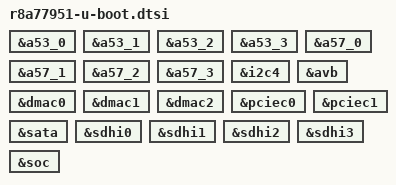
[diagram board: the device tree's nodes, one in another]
// SPDX-License-Identifier: GPL-2.0
/*
 * Device Tree Source extras for U-Boot on R-Car R8A7795 SoC
 *
 * Copyright (C) 2018 Marek Vasut <marek.vasut@gmail.com>
 */

/delete-node/ &ak4613;
/delete-node/ &audma0;
/delete-node/ &audma1;
/delete-node/ &can0;
/delete-node/ &can1;
/delete-node/ &canfd;
/delete-node/ &cluster0_opp;
/delete-node/ &cluster1_opp;
/delete-node/ &csi20;
/delete-node/ &csi40;
/delete-node/ &csi41;
/delete-node/ &drif00;
/delete-node/ &drif01;
/delete-node/ &drif10;
/delete-node/ &drif11;
/delete-node/ &drif20;
/delete-node/ &drif21;
/delete-node/ &drif30;
/delete-node/ &drif31;
/delete-node/ &du;
/delete-node/ &fcpf0;
/delete-node/ &fcpf1;
/delete-node/ &fcpvb0;
/delete-node/ &fcpvb1;
/delete-node/ &fcpvd0;
/delete-node/ &fcpvd1;
/delete-node/ &fcpvd2;
/delete-node/ &fcpvi0;
/delete-node/ &fcpvi1;
/delete-node/ &hdmi0;
/delete-node/ &hdmi1;
/delete-node/ &ipmmu_ds0;
/delete-node/ &ipmmu_ds1;
/delete-node/ &ipmmu_hc;
/delete-node/ &ipmmu_ir;
/delete-node/ &ipmmu_mm;
/delete-node/ &ipmmu_mp0;
/delete-node/ &ipmmu_pv0;
/delete-node/ &ipmmu_pv1;
/delete-node/ &ipmmu_pv2;
/delete-node/ &ipmmu_pv3;
/delete-node/ &ipmmu_rt;
/delete-node/ &ipmmu_vc0;
/delete-node/ &ipmmu_vc1;
/delete-node/ &ipmmu_vi0;
/delete-node/ &ipmmu_vi1;
/delete-node/ &ipmmu_vp0;
/delete-node/ &ipmmu_vp1;
/delete-node/ &lvds0;
/delete-node/ &rcar_sound;
/delete-node/ &sound_card;
/delete-node/ &vin0;
/delete-node/ &vin1;
/delete-node/ &vin2;
/delete-node/ &vin3;
/delete-node/ &vin4;
/delete-node/ &vin5;
/delete-node/ &vin6;
/delete-node/ &vin7;
/delete-node/ &vspbc;
/delete-node/ &vspbd;
/delete-node/ &vspd0;
/delete-node/ &vspd1;
/delete-node/ &vspd2;
/delete-node/ &vspi0;
/delete-node/ &vspi1;

/ {
	/delete-node/ cvbs-in;
	/delete-node/ hdmi-in;
	/delete-node/ hdmi0-out;
	/delete-node/ hdmi1-out;
	/delete-node/ vga-encoder;
	/delete-node/ vga;
};

&a53_0 {
	/delete-property/ operating-points-v2;
};

&a53_1 {
	/delete-property/ operating-points-v2;
};

&a53_2 {
	/delete-property/ operating-points-v2;
};

&a53_3 {
	/delete-property/ operating-points-v2;
};

&a57_0 {
	/delete-property/ operating-points-v2;
};

&a57_1 {
	/delete-property/ operating-points-v2;
};

&a57_2 {
	/delete-property/ operating-points-v2;
};

&a57_3 {
	/delete-property/ operating-points-v2;
};

&i2c4 {
	/delete-node/ video-receiver@70;
};

&avb {
	/delete-property/ iommus;
};

&dmac0 {
	/delete-property/ iommus;
};

&dmac1 {
	/delete-property/ iommus;
};

&dmac2 {
	/delete-property/ iommus;
};

&pciec0 {
	/delete-property/ iommu-map;
};

&pciec1 {
	/delete-property/ iommu-map;
};

&sata {
	/delete-property/ iommus;
};

&sdhi0 {
	/delete-property/ iommus;
};

&sdhi1 {
	/delete-property/ iommus;
};

&sdhi2 {
	/delete-property/ iommus;
};

&sdhi3 {
	/delete-property/ iommus;
};

&soc {
	/delete-node/ fdp1@fe940000;
	/delete-node/ fdp1@fe944000;
	/delete-node/ fdp1@fe948000;
	/delete-node/ imr-lx4@fe860000;
	/delete-node/ imr-lx4@fe870000;
	/delete-node/ imr-lx4@fe880000;
	/delete-node/ imr-lx4@fe890000;
};
